# earlgrey register map
Vendor: lowRISC; File version: snapshot-20191101-1-539-gaf065293
CPU: other 0, little endian, no MPU, no FPU, 0 interrupt priority bits
Registers are 32-bit, read-write, reset 0x0 unless marked. A register's access mark holds for its fields unless they carry their own. Offsets are from the block's base; [hi:lo] are bit positions; lines under a group give offsets from that group; {n}, {i} and the like mark numbered series.

## flash_ctrl
Base 0x40030000
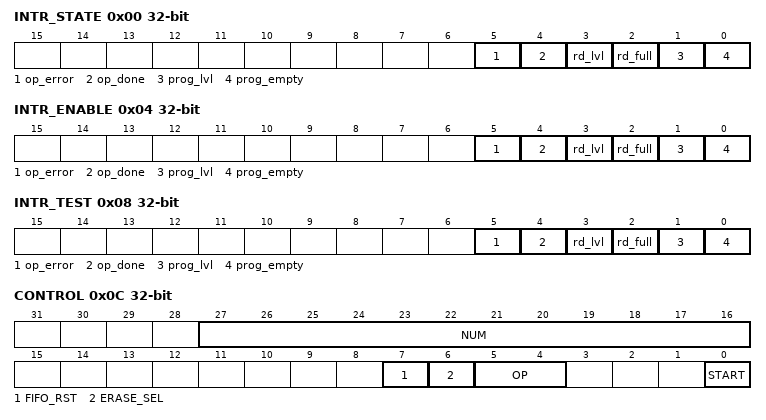
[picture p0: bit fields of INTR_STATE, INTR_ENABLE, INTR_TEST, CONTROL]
0x00 INTR_STATE — Interrupt State Register
  [5] op_error write-1-clears — Operation failed with error
  [4] op_done write-1-clears — Operation complete
  [3] rd_lvl write-1-clears — Read FIFO filled to level
  [2] rd_full write-1-clears — Read FIFO full
  [1] prog_lvl write-1-clears — Program FIFO drained to level
  [0] prog_empty write-1-clears — Program FIFO empty
0x04 INTR_ENABLE — Interrupt Enable Register
  [5] op_error — Enable interrupt when !!INTR_STATE.op_error is set
  [4] op_done — Enable interrupt when !!INTR_STATE.op_done is set
  [3] rd_lvl — Enable interrupt when !!INTR_STATE.rd_lvl is set
  [2] rd_full — Enable interrupt when !!INTR_STATE.rd_full is set
  [1] prog_lvl — Enable interrupt when !!INTR_STATE.prog_lvl is set
  [0] prog_empty — Enable interrupt when !!INTR_STATE.prog_empty is set
0x08 INTR_TEST wo — Interrupt Test Register
  [5] op_error — Write 1 to force !!INTR_STATE.op_error to 1
  [4] op_done — Write 1 to force !!INTR_STATE.op_done to 1
  [3] rd_lvl — Write 1 to force !!INTR_STATE.rd_lvl to 1
  [2] rd_full — Write 1 to force !!INTR_STATE.rd_full to 1
  [1] prog_lvl — Write 1 to force !!INTR_STATE.prog_lvl to 1
  [0] prog_empty — Write 1 to force !!INTR_STATE.prog_empty to 1
0x0C CONTROL
  [27:16] NUM — Number of flash words the flash operation should read or program.
  [7] FIFO_RST — RST FIFOs
  [6] ERASE_SEL — Flash operation selection
  [5:4] OP — Flash operation selection
  [0] START — Start flash transaction. This bit shall only be set after the other fields of the CONTROL register and ADDR have been programmed
0x10 ADDR — Address for flash operation
  [31:0] START — Start address of a flash transaction. Software should supply the full byte address. The flash controller will then truncate the address as needed. For read operations, the flash controller will truncate to the closest, lower word aligned address. For example, if 0x13 is supplied, the controller will perform a read at address 0x10. Program operations behave similarly, the controller does not have read modified write support. For page erases, the controller will truncate to the closest lower page aligned address. Similarly for bank erases, the controller will truncate to the closest lower bank aligned address.
0x14 REGION_CFG_REGWEN group — Memory region registers configuration enable.
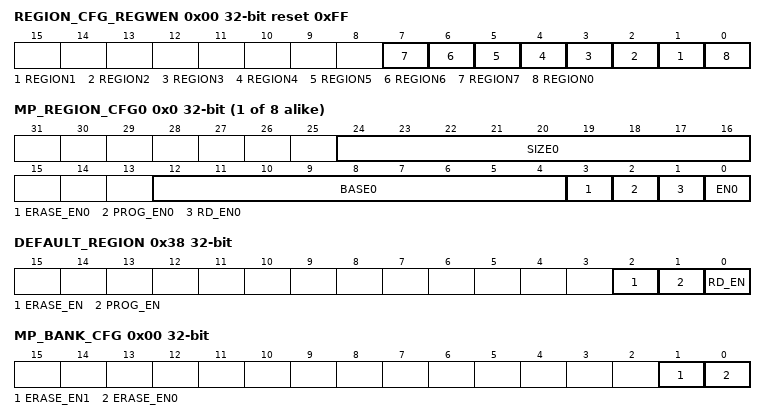
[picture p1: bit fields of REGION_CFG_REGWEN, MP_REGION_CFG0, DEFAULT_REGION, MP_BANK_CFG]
  0x00 REGION_CFG_REGWEN reset 0xFF write-0-clears — Memory region registers configuration enable.
    [n] REGION{n} write-0-clears (n=1..7) — for FLASH_CTRL{n}
    [0] REGION0 write-0-clears — Region register write enable. Once set to 0, it can longer be configured to 1 for FLASH_CTRL0
0x18 MP_REGION_CFG group — Memory protection configuration
  {0x0+4j} MP_REGION_CFG{j} (j=0..7) — Memory protection configuration
    [24:16] SIZE{j} — Region size in number of pages for FLASH_CTRL{j}
    [12:4] BASE{j} — Region base page. Note the granularity is page, not byte or word for FLASH_CTRL{j}
    [3] ERASE_EN{j} — Region can be erased for FLASH_CTRL{j}
    [2] PROG_EN{j} — Region can be programmed for FLASH_CTRL{j}
    [1] RD_EN{j} — Region can be read for FLASH_CTRL{j}
    [0] EN{j} — Region enabled, following fields apply for FLASH_CTRL{j}
0x38 DEFAULT_REGION — Default region permissions
  [2] ERASE_EN — Region can be erased
  [1] PROG_EN — Region can be programmed
  [0] RD_EN — Region can be read
0x3C BANK_CFG_REGWEN reset 0x1 write-0-clears — Bank configuration registers configuration enable.
  [0] BANK write-0-clears — Bank register write enable. Once set to 0, it can longer be configured to 1
0x40 MP_BANK_CFG group — Memory protect bank configuration
  0x00 MP_BANK_CFG — Memory protect bank configuration
    [1] ERASE_EN1 — for FLASH_CTRL1
    [0] ERASE_EN0 — Bank wide erase enable for FLASH_CTRL0
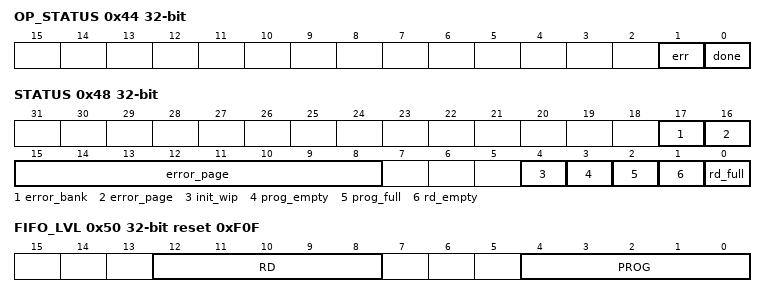
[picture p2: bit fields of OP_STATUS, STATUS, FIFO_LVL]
0x44 OP_STATUS — Flash Operation Status
  [1] err — Flash operation error. Set by HW, cleared by SW
  [0] done — Flash operation done. Set by HW, cleared by SW
0x48 STATUS ro — Flash Controller Status
  [17] error_bank — Flash controller error bank.
  [16:8] error_page — Flash controller error page.
  [4] init_wip — Flash controller undergoing init
  [3] prog_empty — Flash program fifo empty, software must provide data
  [2] prog_full — Flash program fifo full
  [1] rd_empty — Flash read fifo empty
  [0] rd_full — Flash read fifo full, software must consume data
0x4C Scratch — Flash Controller Scratch
  [31:0] data — Flash ctrl scratch register
0x50 FIFO_LVL reset 0xF0F — Programmable depth where fifos should generate interrupts
  [12:8] RD — When the read fifo fills to this level, trigger an interrupt. Default value is set such that interrupt does not trigger at reset.
  [4:0] PROG — When the program fifo drains to this level, trigger an interrupt. Default value is set such that interrupt does not trigger at reset.
{0x54+4i} prog_fifo{i} (i=0..0) wo reset not defined — Flash program fifo. The fifo is 16 entries of 4B flash words
{0x58+4i} rd_fifo{i} (i=0..0) ro reset not defined — Flash read fifo. The fifo is 16 entries of 4B flash words
